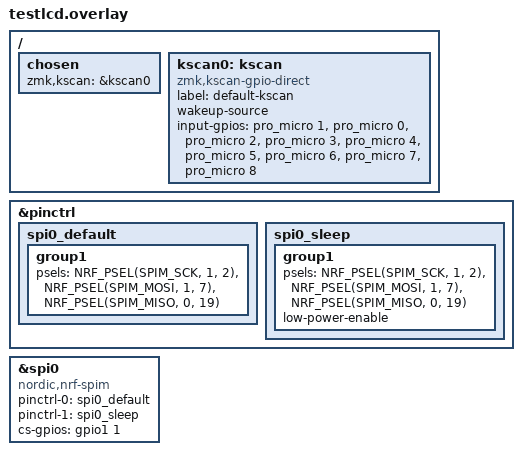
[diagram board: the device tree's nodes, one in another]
&pinctrl {
    spi0_default: spi0_default {
        group1 {
            psels = <NRF_PSEL(SPIM_SCK, 1, 2)>,
                <NRF_PSEL(SPIM_MOSI, 1, 7)>,
                <NRF_PSEL(SPIM_MISO, 0, 19)>; /* GPIO0 19 is not broken on a nice!nano.*/
        };
    };
    spi0_sleep: spi0_sleep {
        group1 {
            psels = <NRF_PSEL(SPIM_SCK, 1, 2)>,
                <NRF_PSEL(SPIM_MOSI, 1, 7)>,
                <NRF_PSEL(SPIM_MISO, 0, 19)>; /* GPIO0 19 is not broken on a nice!nano.*/
            low-power-enable;
        };
    };
};


nice_view_spi: &spi0 {
    compatible = "nordic,nrf-spim";
    pinctrl-0 = <&spi0_default>;
    pinctrl-1 = <&spi0_sleep>;
    pinctrl-names = "default", "sleep";
    cs-gpios = <&gpio1 1 GPIO_ACTIVE_HIGH>;
};

/ {
    chosen {
        zmk,kscan = &kscan0;
    };

    kscan0: kscan {
        compatible = "zmk,kscan-gpio-direct";
		label= "default-kscan";
        wakeup-source;

        input-gpios
            = <&pro_micro 1 (GPIO_ACTIVE_HIGH | GPIO_PULL_DOWN)> 
            , <&pro_micro 0 (GPIO_ACTIVE_HIGH | GPIO_PULL_DOWN)> 
            , <&pro_micro 2 (GPIO_ACTIVE_HIGH | GPIO_PULL_DOWN)> 
			, <&pro_micro 3 (GPIO_ACTIVE_HIGH | GPIO_PULL_DOWN)> 
			, <&pro_micro 4 (GPIO_ACTIVE_HIGH | GPIO_PULL_DOWN)> 
			, <&pro_micro 5 (GPIO_ACTIVE_HIGH | GPIO_PULL_DOWN)> 
			, <&pro_micro 6 (GPIO_ACTIVE_HIGH | GPIO_PULL_DOWN)> 
			, <&pro_micro 7 (GPIO_ACTIVE_HIGH | GPIO_PULL_DOWN)> 
			, <&pro_micro 8 (GPIO_ACTIVE_HIGH | GPIO_PULL_DOWN)> 
            ;


    };



};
